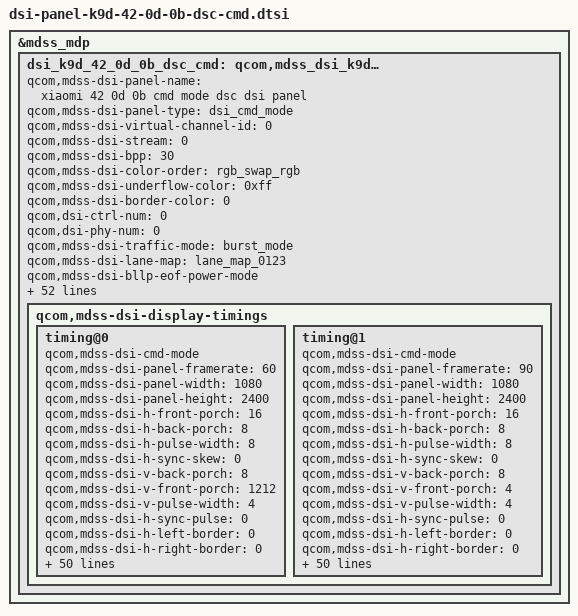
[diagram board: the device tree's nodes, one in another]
&mdss_mdp {
	dsi_k9d_42_0d_0b_dsc_cmd: qcom,mdss_dsi_k9d_42_0d_0b_dsc_cmd {
		qcom,mdss-dsi-panel-name = "xiaomi 42 0d 0b cmd mode dsc dsi panel";
		qcom,mdss-dsi-panel-type = "dsi_cmd_mode";
		qcom,mdss-dsi-virtual-channel-id = <0>;
		qcom,mdss-dsi-stream = <0>;
		qcom,mdss-dsi-bpp = <30>;
		qcom,mdss-dsi-color-order = "rgb_swap_rgb";
		qcom,mdss-dsi-underflow-color = <0xff>;
		qcom,mdss-dsi-border-color = <0>;
		qcom,dsi-ctrl-num = <0>;
		qcom,dsi-phy-num = <0>;
		qcom,mdss-dsi-traffic-mode = "burst_mode";
		qcom,mdss-dsi-lane-map = "lane_map_0123";
		qcom,mdss-dsi-bllp-eof-power-mode;
		qcom,mdss-dsi-bllp-power-mode;
		qcom,mdss-dsi-lane-0-state;
		qcom,mdss-dsi-lane-1-state;
		qcom,mdss-dsi-lane-2-state;
		qcom,mdss-dsi-lane-3-state;
		qcom,mdss-dsi-dma-trigger = "trigger_sw";
		qcom,mdss-dsi-mdp-trigger = "none";
		qcom,mdss-dsi-reset-sequence =  <1 6>, <0 1>, <1 11>;
		qcom,mdss-pan-physical-width-dimension = <695>;
		qcom,mdss-pan-physical-height-dimension = <1545>;
		qcom,mdss-dsi-te-pin-select = <1>;
		qcom,mdss-dsi-wr-mem-start = <0x2c>;
		qcom,mdss-dsi-wr-mem-continue = <0x3c>;
		qcom,mdss-dsi-te-dcs-command = <1>;
		qcom,mdss-dsi-te-check-enable;
		qcom,mdss-dsi-te-using-te-pin;
		qcom,mdss-dsi-tx-eot-append;
		qcom,mdss-dsi-lp11-init;
		qcom,mdss-dsi-bl-inverted-dbv;
		qcom,bl-dsc-cmd-state = "dsi_lp_mode";
		qcom,bl-update-flag = "delay_until_first_frame";

		qcom,mdss-dsi-panel-hdr-enabled;
		qcom,mdss-dsi-panel-hdr-color-primaries = <14500 15500 32000 17000 15500 30000 8000 3000>;

		qcom,mdss-dsi-display-timings {
			timing@0{
				qcom,mdss-dsi-cmd-mode;
				qcom,mdss-dsi-panel-framerate = <60>;
				qcom,mdss-dsi-panel-width = <1080>;
				qcom,mdss-dsi-panel-height = <2400>;
				qcom,mdss-dsi-h-front-porch = <16>;
				qcom,mdss-dsi-h-back-porch = <8>;
				qcom,mdss-dsi-h-pulse-width = <8>;
				qcom,mdss-dsi-h-sync-skew = <0>;
				qcom,mdss-dsi-v-back-porch = <8>;
				qcom,mdss-dsi-v-front-porch = <1212>;
				qcom,mdss-dsi-v-pulse-width = <4>;
				qcom,mdss-dsi-h-sync-pulse = <0>;
				qcom,mdss-dsi-h-left-border = <0>;
				qcom,mdss-dsi-h-right-border = <0>;
				qcom,mdss-dsi-v-top-border = <0>;
				qcom,mdss-dsi-v-bottom-border = <0>;
				qcom,mdss-dsi-panel-clockrate = <682000000>;
				qcom,mdss-dsi-panel-jitter = <0x5 0x1>;
				qcom,mdss-mdp-transfer-time-us = <9500>;
				qcom,mdss-dsi-on-command = [
					/* VESA On */
					15 01 00 00 00 00 02 03 01
					/* CMD2 Page0 */
					39 01 00 00 00 00 03 F0 AA 10
					/* FIX ID == 40 */
					39 01 00 00 00 00 04 E7 00 40 00
					/* ESD check register cofig */
					39 01 00 00 00 00 06 CF 09 07 8B 89 13
					/* HSYNC porch adjustment */
					39 01 00 00 00 00 08 B1 01 EC 00 18 04 E0 00
					39 01 00 00 00 00 03 44 00 03
					/* CMD2 Page2 */
					39 01 00 00 00 00 03 F0 AA 12
					/* VSYNC */
					39 01 00 00 00 00 03 C1 00 0F
					/* Video Trim On */
					39 01 00 00 00 00 12 C3 C1 20 01 37 01 37 01 37 03 A5 03 A5 03 A5 20 00 63
					39 01 00 00 00 00 11 C4 00 00 00 00 00 00 00 00 00 00 00 00 00 00 00 00
					/* TE On */
					05 01 00 00 00 00 02 35 00
					/* Dimming On */
					15 01 00 00 00 00 02 53 20
					/* Demura On */
					15 01 00 00 00 00 02 59 09
					/* Normal brightness */
					39 01 00 00 00 00 03 51 00 00
					/* Enter 60HZ */
					15 01 00 00 00 00 02 6C 00
					/* CMD mode */
					15 01 00 00 00 00 02 6F 02
					/* PPS code */
					39 01 00 00 00 00 33 70 11 00 00 89 30 80 09 60 04 38 00 28
					04 38 04 38 02 00 03 A3 00 20 04 72 00 0F 00 0F 03 14 01 46
					18 00 10 F0 03 0C 20 00 06 0B 0B 33 0E 1C 2A 38 46 54
					15 01 00 00 00 00 02 65 32
					39 01 00 00 00 00 2D 70 62 69 70 77 79 7B 7D 7E 01 02 01 00
					09 40 09 BE 19 FC 19 FA 19 F8 1A 38 1A 78 1A B6 2A B6 2A F4
					2A F4 4B 34 7B F4 00 00 00 00 00 00
					/* CMD2 Page4 */
					39 01 00 00 00 00 03 F0 AA 14
					/* GOA */
					39 01 00 00 00 00 03 B2 03 33
					39 01 00 00 00 00 0D B4 0A 56 00 00 0A 56 00 00 0A 56 00 00
					39 01 00 00 00 00 0A B5 00 17 17 17 17 17 17 06 01
					39 01 00 00 00 00 07 B9 00 00 0A 17 17 17
					39 01 00 00 00 00 0C BC 10 00 00 0A 11 17 69 17 69 17 69
					39 01 00 00 00 00 0C BE 10 10 00 0A 22 17 41 17 41 17 41
					39 01 00 00 00 00 03 FF 5A 81
					15 01 00 00 00 00 02 65 05
					15 01 00 00 00 00 02 F3 0F
					/* LV Detect*/
					39 01 00 00 00 00 03 F0 AA 12
					39 01 00 00 00 00 05 C7 2F 43 32 44
					/* ROUND CORNER ON */
					39 01 00 00 00 00 03 F0 AA 18
					15 01 00 00 00 00 02 B0 13
					15 01 00 00 00 00 02 B2 13
					39 01 00 00 00 00 03 F0 AA 17
					39 01 00 00 00 00 05 B1 00 00 12 00
					39 01 00 00 00 00 17 B2 00 00 00 02 e0 00 0e 00 00 e0 00 00 00 00 20 20 00 40 00 00 20 20
					39 01 00 00 00 00 13 B3 00 40 1A 00 3c 00 80 A8 98 80 A8 80 00 C0 00 00 1F A0
					/* Close high speed command */
					39 01 00 00 00 00 03 F0 AA 10
					39 01 00 00 00 00 02 B3 C7
					/* Adjust of Source and BC up time */
					39 01 00 00 00 00 03 F0 AA 15
					15 01 00 00 00 00 02 C3 01
					39 01 00 00 00 00 09 D2 00 01 04 38 05 C9 0A 00
					15 01 00 00 00 00 02 B1 65
					39 01 00 00 00 00 07 B2 36 02 00 03 30 00
					39 01 00 00 00 00 03 B3 26 41
					39 01 00 00 00 00 07 B4 25 41 00 45 00 00
					39 01 00 00 00 00 07 B5 25 41 00 45 00 00
					39 01 00 00 00 00 07 B6 25 41 00 45 00 00
					39 01 00 00 00 00 07 B7 25 41 00 45 00 00
					39 01 00 00 00 00 07 B8 A4 00 00 25 00 00
					39 01 00 00 00 00 03 BC 07 02
					39 01 00 00 00 00 0C BE 22 44 22 22 44 44 44 44 44 44 00
					39 01 00 00 00 00 03 F0 AA 12
					39 01 00 00 00 00 02 65 08
					39 01 00 00 00 00 05 D2 10 00 01 01
					/* Lock Page */
					39 01 00 00 00 00 03 F0 AA 00
					39 01 00 00 00 00 03 FF 5A 00
					/* Sleep Out */
					05 01 00 00 C8 00 02 11 00
					/* Display On */
					05 01 00 00 00 00 02 29 00];
				qcom,mdss-dsi-off-command = [
					05 01 00 00 14 00 02 28 00
					05 01 00 00 78 00 02 10 00];
				qcom,mdss-dsi-on-command-state = "dsi_lp_mode";
				qcom,mdss-dsi-off-command-state = "dsi_lp_mode";

				qcom,mdss-dsi-timing-switch-command = [
					15 01 00 00 0C 00 02 6C 00];
				qcom,mdss-dsi-timing-switch-command-state = "dsi_lp_mode";

				qcom,mdss-dsi-nolp-command = [
					05 01 00 00 00 00 01 38
					15 01 00 00 00 00 02 6C 00];
				qcom,mdss-dsi-nolp-command-state = "dsi_lp_mode";

				qcom,compression-mode = "dsc";
				qcom,mdss-dsc-version = <0x11>;
				qcom,mdss-dsc-scr-version = <0x0>;
				qcom,mdss-dsc-slice-height = <12>;
				qcom,mdss-dsc-slice-width = <1080>;
				qcom,mdss-dsc-slice-per-pkt = <1>;
				qcom,mdss-dsc-bit-per-component = <10>;
				qcom,mdss-dsc-bit-per-pixel = <8>;
				qcom,mdss-dsc-block-prediction-enable;
			};
			timing@1{
				qcom,mdss-dsi-cmd-mode;
				qcom,mdss-dsi-panel-framerate = <90>;
				qcom,mdss-dsi-panel-width = <1080>;
				qcom,mdss-dsi-panel-height = <2400>;
				qcom,mdss-dsi-h-front-porch = <16>;
				qcom,mdss-dsi-h-back-porch = <8>;
				qcom,mdss-dsi-h-pulse-width = <8>;
				qcom,mdss-dsi-h-sync-skew = <0>;
				qcom,mdss-dsi-v-back-porch = <8>;
				qcom,mdss-dsi-v-front-porch = <4>;
				qcom,mdss-dsi-v-pulse-width = <4>;
				qcom,mdss-dsi-h-sync-pulse = <0>;
				qcom,mdss-dsi-h-left-border = <0>;
				qcom,mdss-dsi-h-right-border = <0>;
				qcom,mdss-dsi-v-top-border = <0>;
				qcom,mdss-dsi-v-bottom-border = <0>;
				qcom,mdss-dsi-panel-clockrate = <682000000>;
				qcom,mdss-dsi-panel-jitter = <0x5 0x1>;
				qcom,mdss-mdp-transfer-time-us = <9500>;
				qcom,mdss-dsi-on-command = [
					/* VESA On */
					15 01 00 00 00 00 02 03 01
					/* CMD2 Page0 */
					39 01 00 00 00 00 03 F0 AA 10
					/* FIX ID == 40 */
					39 01 00 00 00 00 04 E7 00 40 00
					/* ESD check register cofig */
					39 01 00 00 00 00 06 CF 09 07 8B 89 13
					/* HSYNC porch adjustment */
					39 01 00 00 00 00 08 B1 01 EC 00 18 04 E0 00
					39 01 00 00 00 00 03 44 00 03
					/* CMD2 Page2 */
					39 01 00 00 00 00 03 F0 AA 12
					/* VSYNC */
					39 01 00 00 00 00 03 C1 00 0F
					/* Video Trim On */
                                        39 01 00 00 00 00 12 C3 C1 20 01 37 01 37 01 37 03 A5 03 A5 03 A5 20 00 63
                                        39 01 00 00 00 00 11 C4 00 00 00 00 00 00 00 00 00 00 00 00 00 00 00 00
					/* TE On */
					05 01 00 00 00 00 02 35 00
					/* Dimming On */
					15 01 00 00 00 00 02 53 20
					/* Demura On */
					15 01 00 00 00 00 02 59 09
					/* Normal brightness */
					39 01 00 00 00 00 03 51 00 00
					/* Enter 90HZ */
					15 01 00 00 00 00 02 6C 01
					/* CMD mode */
					15 01 00 00 00 00 02 6F 02
					/* CMD2 Page4 */
					39 01 00 00 00 00 03 F0 AA 14
					/* GOA */
					39 01 00 00 00 00 03 B2 03 33
					39 01 00 00 00 00 0D B4 0A 56 00 00 0A 56 00 00 0A 56 00 00
					39 01 00 00 00 00 0A B5 00 17 17 17 17 17 17 06 01
					39 01 00 00 00 00 07 B9 00 00 0A 17 17 17
					39 01 00 00 00 00 0C BC 10 00 00 0A 11 17 69 17 69 17 69
					39 01 00 00 00 00 0C BE 10 10 00 0A 22 17 41 17 41 17 41
					39 01 00 00 00 00 03 FF 5A 81
					15 01 00 00 00 00 02 65 05
					15 01 00 00 00 00 02 F3 0F
					/* LV Detect*/
					39 01 00 00 00 00 03 F0 AA 12
					39 01 00 00 00 00 05 C7 2F 43 32 44
					/* ROUND CORNER ON */
					39 01 00 00 00 00 03 F0 AA 18
					15 01 00 00 00 00 02 B0 13
					15 01 00 00 00 00 02 B2 13
					39 01 00 00 00 00 03 F0 AA 17
					39 01 00 00 00 00 05 B1 00 00 12 00
					39 01 00 00 00 00 17 B2 00 00 00 02 e0 00 0e 00 00 e0 00 00 00 00 20 20 00 40 00 00 20 20
					39 01 00 00 00 00 13 B3 00 40 1A 00 3c 00 80 A8 98 80 A8 80 00 C0 00 00 1F A0
					/* Close high speed command */
					39 01 00 00 00 00 03 F0 AA 10
					39 01 00 00 00 00 02 B3 C7
					/* Adjust of Source and BC up time */
					39 01 00 00 00 00 03 F0 AA 15
					15 01 00 00 00 00 02 C3 01
					39 01 00 00 00 00 09 D2 00 01 04 38 05 C9 0A 00
					15 01 00 00 00 00 02 B1 65
					39 01 00 00 00 00 07 B2 36 02 00 03 30 00
					39 01 00 00 00 00 03 B3 26 41
					39 01 00 00 00 00 07 B4 25 41 00 45 00 00
					39 01 00 00 00 00 07 B5 25 41 00 45 00 00
					39 01 00 00 00 00 07 B6 25 41 00 45 00 00
					39 01 00 00 00 00 07 B7 25 41 00 45 00 00
					39 01 00 00 00 00 07 B8 A4 00 00 25 00 00
					39 01 00 00 00 00 03 BC 07 02
					39 01 00 00 00 00 0C BE 22 44 22 22 44 44 44 44 44 44 00
					39 01 00 00 00 00 03 F0 AA 12
					39 01 00 00 00 00 02 65 08
					39 01 00 00 00 00 05 D2 10 00 01 01
					/* Lock Page */
					39 01 00 00 00 00 03 F0 AA 00
					39 01 00 00 00 00 03 FF 5A 00
					/* Sleep Out */
					05 01 00 00 C8 00 02 11 00
					/* Display On */
					05 01 00 00 00 00 02 29 00];
				qcom,mdss-dsi-off-command = [
					05 01 00 00 14 00 02 28 00
					05 01 00 00 78 00 02 10 00];
				qcom,mdss-dsi-on-command-state = "dsi_lp_mode";
				qcom,mdss-dsi-off-command-state = "dsi_lp_mode";

				qcom,mdss-dsi-timing-switch-command = [
					15 01 00 00 0C 00 02 6C 01];
				qcom,mdss-dsi-timing-switch-command-state = "dsi_lp_mode";

				qcom,mdss-dsi-nolp-command = [
					05 01 00 00 00 00 01 38
					15 01 00 00 00 00 02 6C 01];
				qcom,mdss-dsi-nolp-command-state = "dsi_lp_mode";

				qcom,compression-mode = "dsc";
				qcom,mdss-dsc-version = <0x11>;
				qcom,mdss-dsc-scr-version = <0x0>;
				qcom,mdss-dsc-slice-height = <12>;
				qcom,mdss-dsc-slice-width = <1080>;
				qcom,mdss-dsc-slice-per-pkt = <1>;
				qcom,mdss-dsc-bit-per-component = <10>;
				qcom,mdss-dsc-bit-per-pixel = <8>;
				qcom,mdss-dsc-block-prediction-enable;
			};
		};
	};
};

&dsi_k9d_42_0d_0b_dsc_cmd {
	mi,panel-id = <0x004B3944 0x00420d00>;
	mi,hbm-51-ctl-flag;
	mi,hbm-off-51-index = <1>;
	mi,hbm-on-51-index = <1>;
	mi,hbm-bl-min-level = <1>;
	mi,hbm-bl-max-level = <2047>;
	mi,panel-on-dimming-delay = <120>;
	mi,panel-status-check-interval = <2000>;
	mi,max-brightness-clone = <4095>;
	mi,fp-display-on-optimize-flag;
	mi,thermal-dimming-flag;

	/* IRQF_ONESHOT | IRQF_TRIGGER_HIGH */
	mi,esd-err-irq-gpio = <&tlmm 3 0x2004>;
	qcom,esd-check-enabled;
	qcom,esd-aod-check-enabled;
	qcom,mdss-dsi-panel-status-check-mode = "reg_read";
	qcom,mdss-dsi-panel-status-offset-command = [
		39 01 00 00 00 00 03 FF 5A 80
		15 01 00 00 00 00 02 65 37];
	qcom,mdss-dsi-panel-status-command = [
		06 01 00 00 00 00 01 F5
		06 01 00 00 00 00 01 0A
		06 01 00 00 00 00 01 AA];
	qcom,mdss-dsi-panel-status-read-length = <3 1 1>;
	qcom,mdss-dsi-panel-status-value =
		<0x00 0x00 0x00 0x9C 0x53>,
		<0x00 0x00 0x00 0xDC 0x93>;
	qcom,mdss-dsi-panel-status-command-state = "dsi_lp_mode";
	qcom,mdss-dsi-panel-status-offset-command-state = "dsi_lp_mode";

	qcom,mdss-dsi-display-timings {
		timing@0{
			mi,mdss-dsc-panel-id = <0x004B3944 0x00420d00>;
			mi,mdss-dsi-dimmingon-command = [15 01 00 00 00 00 02 53 28];
			mi,mdss-dsi-dimmingon-command-state = "dsi_hs_mode";
			mi,mdss-dsi-dimmingoff-command = [15 01 00 00 00 00 02 53 20];
			mi,mdss-dsi-dimmingoff-command-state = "dsi_hs_mode";

			mi,mdss-dsi-hbm-on-command = [
				15 01 00 00 00 00 02 53 28
				39 01 00 00 00 00 05 51 0F FF 00 00];
			mi,mdss-dsi-hbm-off-command = [
				15 01 00 00 00 00 02 53 28
				39 01 00 00 00 00 05 51 07 FF 00 00];
			mi,mdss-dsi-hbm-on-command-state = "dsi_lp_mode";
			mi,mdss-dsi-hbm-off-command-state = "dsi_lp_mode";

			mi,mdss-dsi-doze-hbm-command = [
				05 01 00 00 14 00 01 39
				15 01 00 00 00 00 02 6D 00];
			mi,mdss-dsi-doze-lbm-command = [
				05 01 00 00 14 00 01 39
				15 01 00 00 00 00 02 6D 01];
			mi,mdss-dsi-doze-hbm-command-state = "dsi_lp_mode";
			mi,mdss-dsi-doze-lbm-command-state = "dsi_lp_mode";
		};
		timing@1{
			mi,mdss-dsc-panel-id = <0x004B3944 0x00420d00>;
			mi,mdss-dsi-dimmingon-command = [15 01 00 00 00 00 02 53 28];
			mi,mdss-dsi-dimmingon-command-state = "dsi_hs_mode";
			mi,mdss-dsi-dimmingoff-command = [15 01 00 00 00 00 02 53 20];
			mi,mdss-dsi-dimmingoff-command-state = "dsi_hs_mode";

			mi,mdss-dsi-hbm-on-command = [
				15 01 00 00 00 00 02 53 28
				39 01 00 00 00 00 05 51 0F FF 00 00];
			mi,mdss-dsi-hbm-off-command = [
				15 01 00 00 00 00 02 53 28
				39 01 00 00 00 00 05 51 07 FF 00 00];
			mi,mdss-dsi-hbm-on-command-state = "dsi_lp_mode";
			mi,mdss-dsi-hbm-off-command-state = "dsi_lp_mode";

			mi,mdss-dsi-doze-hbm-command = [
				15 01 00 00 11 00 02 6C 00
				05 01 00 00 14 00 01 39
				15 01 00 00 00 00 02 6D 00];
			mi,mdss-dsi-doze-lbm-command = [
				15 01 00 00 11 00 02 6C 00
				05 01 00 00 14 00 01 39
				15 01 00 00 00 00 02 6D 01];
			mi,mdss-dsi-doze-hbm-command-state = "dsi_lp_mode";
			mi,mdss-dsi-doze-lbm-command-state = "dsi_lp_mode";
		};
	};
};
